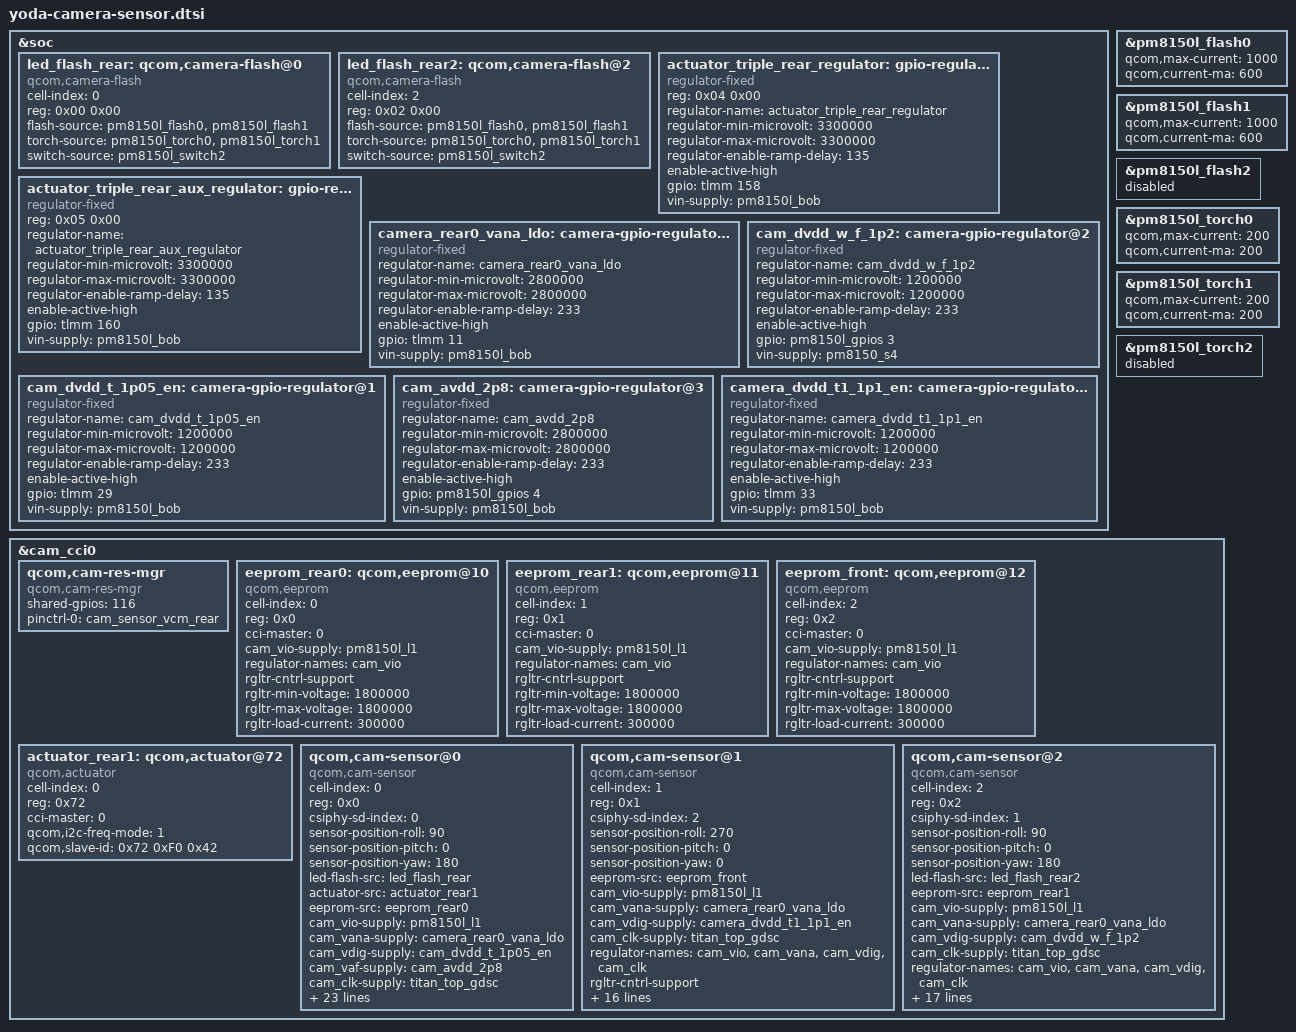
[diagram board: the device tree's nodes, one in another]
/*
 * Copyright (c) 2018, The Linux Foundation. All rights reserved.
 *
 * This program is free software; you can redistribute it and/or modify
 * it under the terms of the GNU General Public License version 2 and
 * only version 2 as published by the Free Software Foundation.
 *
 * This program is distributed in the hope that it will be useful,
 * but WITHOUT ANY WARRANTY; without even the implied warranty of
 * MERCHANTABILITY or FITNESS FOR A PARTICULAR PURPOSE.  See the
 * GNU General Public License for more details.
 */

&soc {
	led_flash_rear: qcom,camera-flash@0 {
		cell-index = <0>;
		reg = <0x00 0x00>;
		compatible = "qcom,camera-flash";
		flash-source = <&pm8150l_flash0 &pm8150l_flash1>;
		torch-source = <&pm8150l_torch0 &pm8150l_torch1>;
		switch-source = <&pm8150l_switch2>;
		status = "ok";
	};
	led_flash_rear2: qcom,camera-flash@2 {
		cell-index = <2>;
		reg = <0x02 0x00>;
		compatible = "qcom,camera-flash";
		flash-source = <&pm8150l_flash0 &pm8150l_flash1>;
		torch-source = <&pm8150l_torch0 &pm8150l_torch1>;
		switch-source = <&pm8150l_switch2>;
		status = "ok";
	};
};
//ASUS_BSP flash +++
&pm8150l_flash0 {
	qcom,max-current = <1000>;
	qcom,current-ma = <600>;
};

&pm8150l_flash1 {
	qcom,max-current = <1000>;
	qcom,current-ma = <600>;
};

&pm8150l_flash2 {
	status = "disabled";
};

&pm8150l_torch0 {
	qcom,max-current = <200>;
	qcom,current-ma = <200>;
};

&pm8150l_torch1 {
	qcom,max-current = <200>;
	qcom,current-ma = <200>;
};

&pm8150l_torch2 {
	status = "disabled";
};

//ASUS_BSP flash ---

&soc {
	actuator_triple_rear_regulator: gpio-regulator@4 {
		compatible = "regulator-fixed";
		reg = <0x04 0x00>;
		regulator-name = "actuator_triple_rear_regulator";
		regulator-min-microvolt = <3300000>;
		regulator-max-microvolt = <3300000>;
		regulator-enable-ramp-delay = <135>;
		enable-active-high;
		gpio = <&tlmm 158 0>;
		vin-supply = <&pm8150l_bob>;
	};

	actuator_triple_rear_aux_regulator: gpio-regulator@5 {
		compatible = "regulator-fixed";
		reg = <0x05 0x00>;
		regulator-name = "actuator_triple_rear_aux_regulator";
		regulator-min-microvolt = <3300000>;
		regulator-max-microvolt = <3300000>;
		regulator-enable-ramp-delay = <135>;
		enable-active-high;
		gpio = <&tlmm 160 0>;
		vin-supply = <&pm8150l_bob>;
	};


	camera_rear0_vana_ldo: camera-gpio-regulator@0 {
		compatible = "regulator-fixed";
		regulator-name = "camera_rear0_vana_ldo";
		regulator-min-microvolt = <2800000>;
		regulator-max-microvolt = <2800000>;
		regulator-enable-ramp-delay = <233>;
		enable-active-high;
		gpio = <&tlmm 11 0>;
		vin-supply = <&pm8150l_bob>;
	};
	cam_dvdd_w_f_1p2: camera-gpio-regulator@2 {
		compatible = "regulator-fixed";
		regulator-name = "cam_dvdd_w_f_1p2";
		regulator-min-microvolt = <1200000>;
		regulator-max-microvolt = <1200000>;
		regulator-enable-ramp-delay = <233>;
		enable-active-high;
		gpio = <&pm8150l_gpios 3 0>;
		vin-supply = <&pm8150_s4>;
	};
	cam_dvdd_t_1p05_en: camera-gpio-regulator@1 {
		compatible = "regulator-fixed";
		regulator-name = "cam_dvdd_t_1p05_en";
		regulator-min-microvolt = <1200000>;
		regulator-max-microvolt = <1200000>;
		regulator-enable-ramp-delay = <233>;
		enable-active-high;
		gpio = <&tlmm 29 0>;
		vin-supply = <&pm8150l_bob>;
	};
	cam_avdd_2p8: camera-gpio-regulator@3 {
		compatible = "regulator-fixed";
		regulator-name = "cam_avdd_2p8";
		regulator-min-microvolt = <2800000>;
		regulator-max-microvolt = <2800000>;
		regulator-enable-ramp-delay = <233>;
		enable-active-high;
		gpio = <&pm8150l_gpios 4 0>;
		vin-supply = <&pm8150l_bob>;
	};
	camera_dvdd_t1_1p1_en: camera-gpio-regulator@6{
		compatible = "regulator-fixed";
		regulator-name = "camera_dvdd_t1_1p1_en";
		regulator-min-microvolt = <1200000>;
		regulator-max-microvolt = <1200000>;
		regulator-enable-ramp-delay = <233>;
		enable-active-high;
		gpio = <&tlmm 33 0>;
		vin-supply = <&pm8150l_bob>;
	};
};

&cam_cci0 {
	qcom,cam-res-mgr {
		compatible = "qcom,cam-res-mgr";
		status = "ok";
    shared-gpios = <116>;
    pinctrl-names = "cam_res_mgr_default";
    pinctrl-0 = <&cam_sensor_vcm_rear>;
	};
	
	eeprom_rear0: qcom,eeprom@10 {
		cell-index = <0>;
		reg = <0x0>;
		cci-master = <0>;
		compatible = "qcom,eeprom";
		cam_vio-supply = <&pm8150l_l1>;
		regulator-names = "cam_vio";
		rgltr-cntrl-support;
		rgltr-min-voltage = <1800000>;
		rgltr-max-voltage = <1800000>;
		rgltr-load-current = <300000>;
		status = "ok";
	};

	eeprom_rear1: qcom,eeprom@11 {
		cell-index = <1>;
		reg = <0x1>;
		cci-master = <0>;
		compatible = "qcom,eeprom";
		cam_vio-supply = <&pm8150l_l1>;
		regulator-names = "cam_vio";
		rgltr-cntrl-support;
		rgltr-min-voltage = <1800000>;
		rgltr-max-voltage = <1800000>;
		rgltr-load-current = <300000>;
		status = "ok";
	};

	eeprom_front: qcom,eeprom@12 {
		cell-index = <2>;
		reg = <0x2>;
		cci-master = <0>;
		compatible = "qcom,eeprom";
		cam_vio-supply = <&pm8150l_l1>;
		regulator-names = "cam_vio";
		rgltr-cntrl-support;
		rgltr-min-voltage = <1800000>;
		rgltr-max-voltage = <1800000>;
		rgltr-load-current = <300000>;
		status = "ok";
	};

	actuator_rear1: qcom,actuator@72 {
		cell-index = <0>;
		reg = <0x72>;
		compatible = "qcom,actuator";
		cci-master = <0>;
		qcom,i2c-freq-mode = <1>;
		qcom,slave-id = <0x72 0xF0 0x42>;
		status = "ok";
	};


	qcom,cam-sensor@0 {
		cell-index = <0>;
		compatible = "qcom,cam-sensor";
		reg = <0x0>;
		csiphy-sd-index = <0>;
		sensor-position-roll = <90>;
		sensor-position-pitch = <0>;
		sensor-position-yaw = <180>;
		led-flash-src = <&led_flash_rear>;
		actuator-src = <&actuator_rear1>;
		eeprom-src = <&eeprom_rear0>;
		cam_vio-supply = <&pm8150l_l1>;
		cam_vana-supply = <&camera_rear0_vana_ldo>;
		cam_vdig-supply = <&cam_dvdd_t_1p05_en>;
		cam_vaf-supply = <&cam_avdd_2p8>;
		cam_clk-supply = <&titan_top_gdsc>;
		regulator-names = "cam_vio", "cam_vana", "cam_vdig", "cam_vaf", "cam_clk";
		rgltr-cntrl-support;
		rgltr-min-voltage = <1800000 2800000 1200000 2800000 0>;
		rgltr-max-voltage = <1800000 2800000 1200000 2800000 0>;
		rgltr-load-current = <0 80000 1200000 0 0 0>;
		gpio-no-mux = <0>;
		pinctrl-names = "cam_default", "cam_suspend";
		pinctrl-0 = <&cam_sensor_mclk0_active>;
		pinctrl-1 = <&cam_sensor_mclk0_suspend>;
		gpios = <&tlmm 13 0>,
			      <&tlmm 28 0>,
            <&tlmm 166 0>;
		gpio-reset = <1>;
    gpio-standby=<2>;
		gpio-req-tbl-num = <0 1 2>;
		gpio-req-tbl-flags = <1 0 0>;
		gpio-req-tbl-label = "CAMIF_MCLK0",
					"CAM_RESET0",
          "CAM_STANDBY0";
		sensor-mode = <0>;
		cci-master = <0>;
		status = "ok";
		clocks = <&clock_camcc CAM_CC_MCLK0_CLK>;
		clock-names = "cam_clk";
		clock-cntl-level = "turbo";
		clock-rates = <19200000>;
	};
	qcom,cam-sensor@1 {
		cell-index = <1>;
		compatible = "qcom,cam-sensor";
		reg = <0x1>;
		csiphy-sd-index = <2>;
		sensor-position-roll = <270>;
		sensor-position-pitch = <0>;
		sensor-position-yaw = <0>;
		//led-flash-src = <&led_flash_rear>;
		eeprom-src = <&eeprom_front>;
		cam_vio-supply = <&pm8150l_l1>;
		cam_vana-supply = <&camera_rear0_vana_ldo>;
		cam_vdig-supply = <&camera_dvdd_t1_1p1_en>;
		cam_clk-supply = <&titan_top_gdsc>;
		regulator-names = "cam_vio", "cam_vana", "cam_vdig",
			"cam_clk";
		rgltr-cntrl-support;
		rgltr-min-voltage = <1800000 2800000 1200000 0>;
		rgltr-max-voltage = <1800000 2800000 1200000 0>;
		rgltr-load-current = <0 80000 1200000 0>;
		gpio-no-mux = <0>;
		pinctrl-names = "cam_default", "cam_suspend";
		pinctrl-0 = <&cam_sensor_mclk2_active>;
		pinctrl-1 = <&cam_sensor_mclk2_suspend>;
		gpios = <&tlmm 15 0>,
			<&tlmm 12 0>;
		gpio-reset = <1>;
		gpio-req-tbl-num = <0 1>;
		gpio-req-tbl-flags = <1 0>;
		gpio-req-tbl-label = "CAMIF_MCLK2",
					"CAM_RESET2";
		sensor-mode = <0>;
		cci-master = <0>;
		status = "ok";
		clocks = <&clock_camcc CAM_CC_MCLK2_CLK>;
		clock-names = "cam_clk";
		clock-cntl-level = "turbo";
		clock-rates = <24000000>;
	};
	qcom,cam-sensor@2 {
		cell-index = <2>;
		compatible = "qcom,cam-sensor";
		reg = <0x2>;
		csiphy-sd-index = <1>;
		sensor-position-roll = <90>;
		sensor-position-pitch = <0>;
		sensor-position-yaw = <180>;
		led-flash-src = <&led_flash_rear2>;
		eeprom-src = <&eeprom_rear1>;
		cam_vio-supply = <&pm8150l_l1>;
		cam_vana-supply = <&camera_rear0_vana_ldo>;
		cam_vdig-supply = <&cam_dvdd_w_f_1p2>;
		cam_clk-supply = <&titan_top_gdsc>;
		regulator-names = "cam_vio", "cam_vana", "cam_vdig",
			"cam_clk";
		rgltr-cntrl-support;
		rgltr-min-voltage = <1800000 2800000 1200000 0>;
		rgltr-max-voltage = <1800000 2800000 1200000 0>;
		rgltr-load-current = <0 80000 1200000 0>;
		gpio-no-mux = <0>;
		pinctrl-names = "cam_default", "cam_suspend";
		pinctrl-0 = <&cam_sensor_mclk1_active>;
		pinctrl-1 = <&cam_sensor_mclk1_suspend>;
		gpios = <&tlmm 14 0>,
			<&tlmm 30 0>;
		gpio-reset = <1>;
		gpio-req-tbl-num = <0 1>;
		gpio-req-tbl-flags = <1 0>;
		gpio-req-tbl-label = "CAMIF_MCLK1",
					"CAM_RESET1";
		sensor-mode = <0>;
		cci-master = <1>;
		status = "ok";
		clocks = <&clock_camcc CAM_CC_MCLK1_CLK>;
		clock-names = "cam_clk";
		clock-cntl-level = "turbo";
		clock-rates = <19200000>;
	};
};

